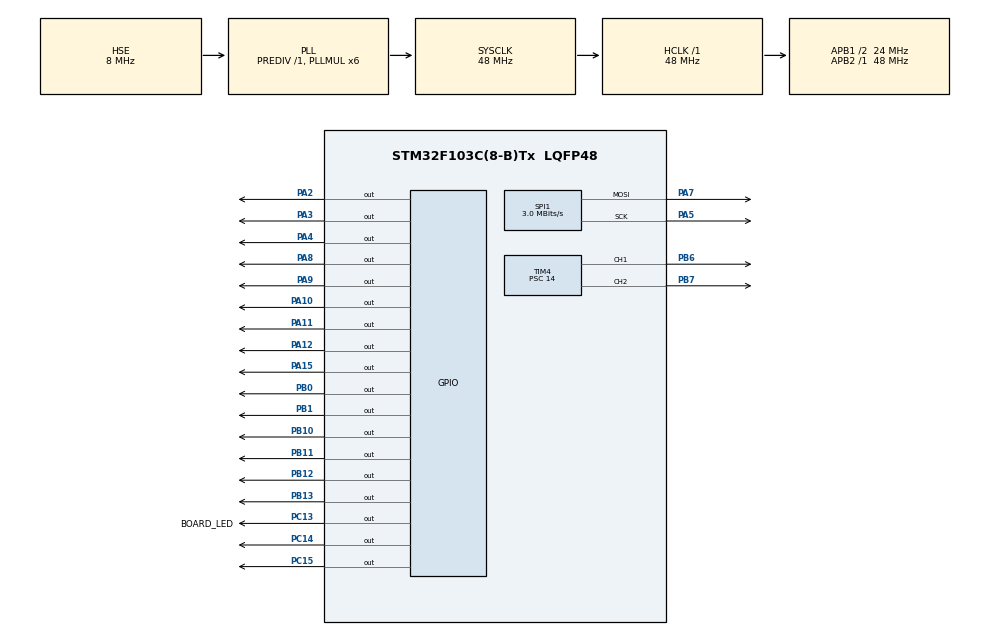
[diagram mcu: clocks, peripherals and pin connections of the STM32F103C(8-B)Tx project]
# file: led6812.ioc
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Dma.Request0=SPI1_TX
Dma.SPI1_TX.0.Direction=DMA_MEMORY_TO_PERIPH
Dma.SPI1_TX.0.Instance=DMA1_Channel3
Dma.SPI1_TX.0.MemDataAlignment=DMA_MDATAALIGN_BYTE
Dma.SPI1_TX.0.MemInc=DMA_MINC_ENABLE
Dma.SPI1_TX.0.Mode=DMA_NORMAL
Dma.SPI1_TX.0.PeriphDataAlignment=DMA_PDATAALIGN_BYTE
Dma.SPI1_TX.0.PeriphInc=DMA_PINC_DISABLE
Dma.SPI1_TX.0.Priority=DMA_PRIORITY_HIGH
FREERTOS.INCLUDE_uxTaskPriorityGet=0
FREERTOS.INCLUDE_vTaskDelayUntil=1
FREERTOS.INCLUDE_vTaskDelete=0
FREERTOS.INCLUDE_vTaskPrioritySet=0
FREERTOS.INCLUDE_vTaskSuspend=1
FREERTOS.MEMORY_ALLOCATION=1
FREERTOS.Tasks01=mainTask,3,256,StartMainTask,As weak,NULL,Static,defaultTaskBuffer,defaultTaskControlBlock;ctrlTask,0,128,StartCtrlTask,As external,NULL,Static,myTask02Buffer,myTask02ControlBlock
FREERTOS.configCHECK_FOR_STACK_OVERFLOW=0
FREERTOS.configENABLE_BACKWARD_COMPATIBILITY=0
FREERTOS.configGENERATE_RUN_TIME_STATS=1
FREERTOS.configIDLE_SHOULD_YIELD=0
FREERTOS.configMINIMAL_STACK_SIZE=128
FREERTOS.configRECORD_STACK_HIGH_ADDRESS=1
FREERTOS.configUSE_MUTEXES=0
FREERTOS.configUSE_NEWLIB_REENTRANT=1
FREERTOS.configUSE_PREEMPTION=1
FREERTOS.configUSE_STATS_FORMATTING_FUNCTIONS=1
FREERTOS.configUSE_TIMERS=0
FREERTOS.configUSE_TRACE_FACILITY=1
FREERTOS.copyHeapFile=0
Mcu.Family=STM32F1
Mcu.Name=STM32F103C(8-B)Tx
Mcu.Package=LQFP48
NVIC.DMA1_Channel3_IRQn=true\:5\:0\:false\:false\:true\:true\:false\:true\:true
NVIC.PriorityGroup=NVIC_PRIORITYGROUP_4
NVIC.TIM1_UP_IRQn=true\:15\:0\:false\:false\:true\:false\:false\:true\:true
NVIC.TimeBase=TIM1_UP_IRQn
NVIC.TimeBaseIP=TIM1
PA10.Signal=GPIO_Output
PA11.Signal=GPIO_Output
PA12.Signal=GPIO_Output
PA13.Mode=Trace_Asynchronous_SW
PA13.Signal=SYS_JTMS-SWDIO
PA14.Mode=Trace_Asynchronous_SW
PA14.Signal=SYS_JTCK-SWCLK
PA15.Signal=GPIO_Output
PA2.Signal=GPIO_Output
PA3.Signal=GPIO_Output
PA4.Signal=GPIO_Output
PA5.Mode=TX_Only_Simplex_Unidirect_Master
PA5.Signal=SPI1_SCK
PA7.Mode=TX_Only_Simplex_Unidirect_Master
PA7.Signal=SPI1_MOSI
PA8.Signal=GPIO_Output
PA9.Signal=GPIO_Output
PB0.Signal=GPIO_Output
PB1.Signal=GPIO_Output
PB10.Signal=GPIO_Output
PB11.Signal=GPIO_Output
PB12.Signal=GPIO_Output
PB13.Signal=GPIO_Output
PB3.Mode=Trace_Asynchronous_SW
PB3.Signal=SYS_JTDO-TRACESWO
PB6.Signal=S_TIM4_CH1
PB7.Signal=S_TIM4_CH2
PC13-TAMPER-RTC.GPIO_Label=BOARD_LED
PC13-TAMPER-RTC.Signal=GPIO_Output
PC14-OSC32_IN.Signal=GPIO_Output
PC15-OSC32_OUT.Signal=GPIO_Output
PD0-OSC_IN.Mode=HSE-External-Oscillator
PD0-OSC_IN.Signal=RCC_OSC_IN
PD1-OSC_OUT.Mode=HSE-External-Oscillator
PD1-OSC_OUT.Signal=RCC_OSC_OUT
ProjectManager.HeapSize=0x200
ProjectManager.StackSize=0x400
ProjectManager.TargetToolchain=STM32CubeIDE
RCC.AHBFreq_Value=48000000
RCC.APB1CLKDivider=RCC_HCLK_DIV2
RCC.APB1Freq_Value=24000000
RCC.APB1TimFreq_Value=48000000
RCC.APB2Freq_Value=48000000
RCC.APB2TimFreq_Value=48000000
RCC.HCLKFreq_Value=48000000
RCC.PLLMUL=RCC_PLL_MUL6
RCC.PLLSourceVirtual=RCC_PLLSOURCE_HSE
RCC.SYSCLKFreq_VALUE=48000000
RCC.SYSCLKSource=RCC_SYSCLKSOURCE_PLLCLK
RCC.USBFreq_Value=48000000
SH.S_TIM4_CH1.0=TIM4_CH1,PWM Generation1 CH1
SH.S_TIM4_CH2.0=TIM4_CH2,PWM Generation2 CH2
SPI1.BaudRatePrescaler=SPI_BAUDRATEPRESCALER_16
SPI1.CalculateBaudRate=3.0 MBits/s
SPI1.Direction=SPI_DIRECTION_2LINES
SPI1.Mode=SPI_MODE_MASTER
SPI1.VirtualType=VM_MASTER
TIM2.Channel-PWM\ Generation1\ No\ Output=TIM_CHANNEL_1
TIM3.Channel-PWM\ Generation1\ No\ Output=TIM_CHANNEL_1
TIM4.AutoReloadPreload=TIM_AUTORELOAD_PRELOAD_ENABLE
TIM4.Channel-PWM\ Generation1\ CH1=TIM_CHANNEL_1
TIM4.Channel-PWM\ Generation2\ CH2=TIM_CHANNEL_2
TIM4.Period=64000
TIM4.Prescaler=14
TIM4.Pulse-PWM\ Generation1\ CH1=5000
TIM4.Pulse-PWM\ Generation2\ CH2=5000
VP_FREERTOS_VS_CMSIS_V1.Mode=CMSIS_V1
VP_SYS_VS_tim1.Mode=TIM1
VP_TIM2_VS_no_output1.Mode=PWM Generation1 No Output
VP_TIM3_VS_no_output1.Mode=PWM Generation1 No Output
board=custom

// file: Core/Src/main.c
/* USER CODE BEGIN Header */
/**
  ******************************************************************************
  * @file           : main.c
  * @brief          : Main program body
  ******************************************************************************
  * @attention
  *
  * Copyright (c) 2023 STMicroelectronics.
  * All rights reserved.
  *
  * This software is licensed under terms that can be found in the LICENSE file
  * in the root directory of this software component.
  * If no LICENSE file comes with this software, it is provided AS-IS.
  *
  ******************************************************************************
  */
/* USER CODE END Header */
#include "main.h"
#include "cmsis_os.h"

/* USER CODE BEGIN Includes */
#include "../../../Led/ledtask.h"
/* USER CODE END Includes */

SPI_HandleTypeDef hspi1;
DMA_HandleTypeDef hdma_spi1_tx;

TIM_HandleTypeDef htim2;
TIM_HandleTypeDef htim3;
TIM_HandleTypeDef htim4;

osThreadId mainTaskHandle;
uint32_t defaultTaskBuffer[ 256 ];
osStaticThreadDef_t defaultTaskControlBlock;
osThreadId ctrlTaskHandle;
uint32_t myTask02Buffer[ 128 ];
osStaticThreadDef_t myTask02ControlBlock;

void SystemClock_Config(void);
static void MX_GPIO_Init(void);
static void MX_DMA_Init(void);
static void MX_TIM4_Init(void);
static void MX_TIM2_Init(void);
static void MX_TIM3_Init(void);
static void MX_SPI1_Init(void);
void StartMainTask(void const * argument);
extern void StartCtrlTask(void const * argument);

int main(void)
{

  /* MCU Configuration--------------------------------------------------------*/

  /* Reset of all peripherals, Initializes the Flash interface and the Systick. */
  HAL_Init();

  /* Configure the system clock */
  SystemClock_Config();

  /* Initialize all configured peripherals */
  MX_GPIO_Init();
  MX_DMA_Init();
  MX_TIM4_Init();
  MX_TIM2_Init();
  MX_TIM3_Init();
  MX_SPI1_Init();

  /* Create the thread(s) */
  /* definition and creation of mainTask */
  osThreadStaticDef(mainTask, StartMainTask, osPriorityRealtime, 0, 256, defaultTaskBuffer, &defaultTaskControlBlock);
  mainTaskHandle = osThreadCreate(osThread(mainTask), NULL);

  /* definition and creation of ctrlTask */
  osThreadStaticDef(ctrlTask, StartCtrlTask, osPriorityNormal, 0, 128, myTask02Buffer, &myTask02ControlBlock);
  ctrlTaskHandle = osThreadCreate(osThread(ctrlTask), NULL);

  /* Start scheduler */
  osKernelStart();

  /* We should never get here as control is now taken by the scheduler */
  /* Infinite loop */
  while (1)
  {

  }
}

void SystemClock_Config(void)
{
  RCC_OscInitTypeDef RCC_OscInitStruct = {0};
  RCC_ClkInitTypeDef RCC_ClkInitStruct = {0};

  /** Initializes the RCC Oscillators according to the specified parameters
  * in the RCC_OscInitTypeDef structure.
  */
  RCC_OscInitStruct.OscillatorType = RCC_OSCILLATORTYPE_HSE;
  RCC_OscInitStruct.HSEState = RCC_HSE_ON;
  RCC_OscInitStruct.HSEPredivValue = RCC_HSE_PREDIV_DIV1;
  RCC_OscInitStruct.HSIState = RCC_HSI_ON;
  RCC_OscInitStruct.PLL.PLLState = RCC_PLL_ON;
  RCC_OscInitStruct.PLL.PLLSource = RCC_PLLSOURCE_HSE;
  RCC_OscInitStruct.PLL.PLLMUL = RCC_PLL_MUL6;
  if (HAL_RCC_OscConfig(&RCC_OscInitStruct) != HAL_OK)
  {
    Error_Handler();
  }

  /** Initializes the CPU, AHB and APB buses clocks
  */
  RCC_ClkInitStruct.ClockType = RCC_CLOCKTYPE_HCLK|RCC_CLOCKTYPE_SYSCLK
                              |RCC_CLOCKTYPE_PCLK1|RCC_CLOCKTYPE_PCLK2;
  RCC_ClkInitStruct.SYSCLKSource = RCC_SYSCLKSOURCE_PLLCLK;
  RCC_ClkInitStruct.AHBCLKDivider = RCC_SYSCLK_DIV1;
  RCC_ClkInitStruct.APB1CLKDivider = RCC_HCLK_DIV2;
  RCC_ClkInitStruct.APB2CLKDivider = RCC_HCLK_DIV1;

  if (HAL_RCC_ClockConfig(&RCC_ClkInitStruct, FLASH_LATENCY_1) != HAL_OK)
  {
    Error_Handler();
  }
}

static void MX_SPI1_Init(void)
{

  /* SPI1 parameter configuration*/
  hspi1.Instance = SPI1;
  hspi1.Init.Mode = SPI_MODE_MASTER;
  hspi1.Init.Direction = SPI_DIRECTION_2LINES;
  hspi1.Init.DataSize = SPI_DATASIZE_8BIT;
  hspi1.Init.CLKPolarity = SPI_POLARITY_LOW;
  hspi1.Init.CLKPhase = SPI_PHASE_1EDGE;
  hspi1.Init.NSS = SPI_NSS_SOFT;
  hspi1.Init.BaudRatePrescaler = SPI_BAUDRATEPRESCALER_16;
  hspi1.Init.FirstBit = SPI_FIRSTBIT_MSB;
  hspi1.Init.TIMode = SPI_TIMODE_DISABLE;
  hspi1.Init.CRCCalculation = SPI_CRCCALCULATION_DISABLE;
  hspi1.Init.CRCPolynomial = 10;
  if (HAL_SPI_Init(&hspi1) != HAL_OK)
  {
    Error_Handler();
  }

}

static void MX_TIM2_Init(void)
{

  TIM_MasterConfigTypeDef sMasterConfig = {0};
  TIM_OC_InitTypeDef sConfigOC = {0};

  htim2.Instance = TIM2;
  htim2.Init.Prescaler = 0;
  htim2.Init.CounterMode = TIM_COUNTERMODE_UP;
  htim2.Init.Period = 65535;
  htim2.Init.ClockDivision = TIM_CLOCKDIVISION_DIV1;
  htim2.Init.AutoReloadPreload = TIM_AUTORELOAD_PRELOAD_DISABLE;
  if (HAL_TIM_PWM_Init(&htim2) != HAL_OK)
  {
    Error_Handler();
  }
  sMasterConfig.MasterOutputTrigger = TIM_TRGO_RESET;
  sMasterConfig.MasterSlaveMode = TIM_MASTERSLAVEMODE_DISABLE;
  if (HAL_TIMEx_MasterConfigSynchronization(&htim2, &sMasterConfig) != HAL_OK)
  {
    Error_Handler();
  }
  sConfigOC.OCMode = TIM_OCMODE_PWM1;
  sConfigOC.Pulse = 0;
  sConfigOC.OCPolarity = TIM_OCPOLARITY_HIGH;
  sConfigOC.OCFastMode = TIM_OCFAST_DISABLE;
  if (HAL_TIM_PWM_ConfigChannel(&htim2, &sConfigOC, TIM_CHANNEL_1) != HAL_OK)
  {
    Error_Handler();
  }

}

static void MX_TIM3_Init(void)
{

  TIM_MasterConfigTypeDef sMasterConfig = {0};
  TIM_OC_InitTypeDef sConfigOC = {0};

  htim3.Instance = TIM3;
  htim3.Init.Prescaler = 0;
  htim3.Init.CounterMode = TIM_COUNTERMODE_UP;
  htim3.Init.Period = 65535;
  htim3.Init.ClockDivision = TIM_CLOCKDIVISION_DIV1;
  htim3.Init.AutoReloadPreload = TIM_AUTORELOAD_PRELOAD_DISABLE;
  if (HAL_TIM_PWM_Init(&htim3) != HAL_OK)
  {
    Error_Handler();
  }
  sMasterConfig.MasterOutputTrigger = TIM_TRGO_RESET;
  sMasterConfig.MasterSlaveMode = TIM_MASTERSLAVEMODE_DISABLE;
  if (HAL_TIMEx_MasterConfigSynchronization(&htim3, &sMasterConfig) != HAL_OK)
  {
    Error_Handler();
  }
  sConfigOC.OCMode = TIM_OCMODE_PWM1;
  sConfigOC.Pulse = 0;
  sConfigOC.OCPolarity = TIM_OCPOLARITY_HIGH;
  sConfigOC.OCFastMode = TIM_OCFAST_DISABLE;
  if (HAL_TIM_PWM_ConfigChannel(&htim3, &sConfigOC, TIM_CHANNEL_1) != HAL_OK)
  {
    Error_Handler();
  }

}

static void MX_TIM4_Init(void)
{

  TIM_MasterConfigTypeDef sMasterConfig = {0};
  TIM_OC_InitTypeDef sConfigOC = {0};

  htim4.Instance = TIM4;
  htim4.Init.Prescaler = 14;
  htim4.Init.CounterMode = TIM_COUNTERMODE_UP;
  htim4.Init.Period = 64000;
  htim4.Init.ClockDivision = TIM_CLOCKDIVISION_DIV1;
  htim4.Init.AutoReloadPreload = TIM_AUTORELOAD_PRELOAD_ENABLE;
  if (HAL_TIM_PWM_Init(&htim4) != HAL_OK)
  {
    Error_Handler();
  }
  sMasterConfig.MasterOutputTrigger = TIM_TRGO_RESET;
  sMasterConfig.MasterSlaveMode = TIM_MASTERSLAVEMODE_DISABLE;
  if (HAL_TIMEx_MasterConfigSynchronization(&htim4, &sMasterConfig) != HAL_OK)
  {
    Error_Handler();
  }
  sConfigOC.OCMode = TIM_OCMODE_PWM1;
  sConfigOC.Pulse = 5000;
  sConfigOC.OCPolarity = TIM_OCPOLARITY_HIGH;
  sConfigOC.OCFastMode = TIM_OCFAST_DISABLE;
  if (HAL_TIM_PWM_ConfigChannel(&htim4, &sConfigOC, TIM_CHANNEL_1) != HAL_OK)
  {
    Error_Handler();
  }
  if (HAL_TIM_PWM_ConfigChannel(&htim4, &sConfigOC, TIM_CHANNEL_2) != HAL_OK)
  {
    Error_Handler();
  }
  HAL_TIM_MspPostInit(&htim4);

}

static void MX_DMA_Init(void)
{

  /* DMA controller clock enable */
  __HAL_RCC_DMA1_CLK_ENABLE();

  /* DMA interrupt init */
  /* DMA1_Channel3_IRQn interrupt configuration */
  HAL_NVIC_SetPriority(DMA1_Channel3_IRQn, 5, 0);
  HAL_NVIC_EnableIRQ(DMA1_Channel3_IRQn);

}

static void MX_GPIO_Init(void)
{
  GPIO_InitTypeDef GPIO_InitStruct = {0};

  /* GPIO Ports Clock Enable */
  __HAL_RCC_GPIOC_CLK_ENABLE();
  __HAL_RCC_GPIOD_CLK_ENABLE();
  __HAL_RCC_GPIOA_CLK_ENABLE();
  __HAL_RCC_GPIOB_CLK_ENABLE();

  /*Configure GPIO pin Output Level */
  HAL_GPIO_WritePin(GPIOC, BOARD_LED_Pin|GPIO_PIN_14|GPIO_PIN_15, GPIO_PIN_RESET);

  /*Configure GPIO pin Output Level */
  HAL_GPIO_WritePin(GPIOA, GPIO_PIN_2|GPIO_PIN_3|GPIO_PIN_4|GPIO_PIN_8
                          |GPIO_PIN_9|GPIO_PIN_10|GPIO_PIN_11|GPIO_PIN_12
                          |GPIO_PIN_15, GPIO_PIN_RESET);

  /*Configure GPIO pin Output Level */
  HAL_GPIO_WritePin(GPIOB, GPIO_PIN_0|GPIO_PIN_1|GPIO_PIN_10|GPIO_PIN_11
                          |GPIO_PIN_12|GPIO_PIN_13, GPIO_PIN_RESET);

  /*Configure GPIO pins : BOARD_LED_Pin PC14 PC15 */
  GPIO_InitStruct.Pin = BOARD_LED_Pin|GPIO_PIN_14|GPIO_PIN_15;
  GPIO_InitStruct.Mode = GPIO_MODE_OUTPUT_PP;
  GPIO_InitStruct.Pull = GPIO_NOPULL;
  GPIO_InitStruct.Speed = GPIO_SPEED_FREQ_LOW;
  HAL_GPIO_Init(GPIOC, &GPIO_InitStruct);

  /*Configure GPIO pins : PA2 PA3 PA4 PA8
                           PA9 PA10 PA11 PA12
                           PA15 */
  GPIO_InitStruct.Pin = GPIO_PIN_2|GPIO_PIN_3|GPIO_PIN_4|GPIO_PIN_8
                          |GPIO_PIN_9|GPIO_PIN_10|GPIO_PIN_11|GPIO_PIN_12
                          |GPIO_PIN_15;
  GPIO_InitStruct.Mode = GPIO_MODE_OUTPUT_PP;
  GPIO_InitStruct.Pull = GPIO_NOPULL;
  GPIO_InitStruct.Speed = GPIO_SPEED_FREQ_LOW;
  HAL_GPIO_Init(GPIOA, &GPIO_InitStruct);

  /*Configure GPIO pins : PB0 PB1 PB10 PB11
                           PB12 PB13 */
  GPIO_InitStruct.Pin = GPIO_PIN_0|GPIO_PIN_1|GPIO_PIN_10|GPIO_PIN_11
                          |GPIO_PIN_12|GPIO_PIN_13;
  GPIO_InitStruct.Mode = GPIO_MODE_OUTPUT_PP;
  GPIO_InitStruct.Pull = GPIO_NOPULL;
  GPIO_InitStruct.Speed = GPIO_SPEED_FREQ_LOW;
  HAL_GPIO_Init(GPIOB, &GPIO_InitStruct);

}

__weak void StartMainTask(void const * argument)
{
  for(;;)
  {
    osDelay(1);
  }
}

void HAL_TIM_PeriodElapsedCallback(TIM_HandleTypeDef *htim)
{
  if (htim->Instance == TIM1) {
    HAL_IncTick();
  }
  /* USER CODE BEGIN Callback 1 */
  if (htim->Instance == TIM1) {
	  static int t = 0;
	  static int nwake=0;
	  t++;
	  // 100 Hz
	  if ((0==(t%10)) && mainTaskHandle) {
		  BaseType_t higher=0;
		  nwake++;

		  xTaskNotifyFromISR(mainTaskHandle, NOTIF_TICK, eSetBits, &higher);
		  portYIELD_FROM_ISR(higher);
	  }
  }
  /* USER CODE END Callback 1 */
}

void Error_Handler(void)
{
  __disable_irq();
  while (1)
  {
  }
}
